VERSION ""

NS_ :

BS_:

BU_: IRTS_RL TLM DAS STEER IRTS_FL DAS STEER DAS IRTS_FR IRTS_FL DAS DAS TELEMETRY CONTROL DAS DAS DAS DAS DAS TELEMETRY DAS STEER IRTS_FR DAS IRTS_RR STEER DAS DAS IRTS_FR IRTS_FL IRTS_RR IRTS_FR DAS IRTS_RR IRTS_FL DAS TLM DAS IMU DAS DAS DAS STEER DAS IRTS_RL TLM IRTS_RR IRTS_RL TLM IMU STEER IRTS_RL

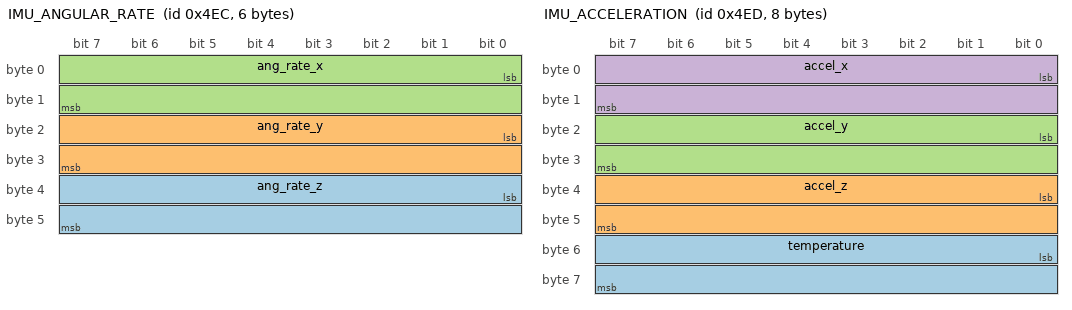
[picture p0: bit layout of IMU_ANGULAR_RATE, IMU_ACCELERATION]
BO_ 1260 IMU_ANGULAR_RATE: 6 Vector__XXX
 SG_ ang_rate_z : 32|16@1+ (0.05982905982905983,0) [0|245] "" Vector__XXX
 SG_ ang_rate_y : 16|16@1+ (0.05982905982905983,0) [0|245] "" Vector__XXX
 SG_ ang_rate_x : 0|16@1+ (0.05982905982905983,0) [0|245] "" Vector__XXX

BO_ 1261 IMU_ACCELERATION: 8 Vector__XXX
 SG_ temperature : 48|16@1- (1,-32768) [-32768|32767] "" Vector__XXX
 SG_ accel_z : 32|16@1+ (0.007820136852394917,0) [0|8] "" Vector__XXX
 SG_ accel_y : 16|16@1+ (0.007820136852394917,0) [0|8] "" Vector__XXX
 SG_ accel_x : 0|16@1+ (0.007820136852394917,0) [0|8] "" Vector__XXX

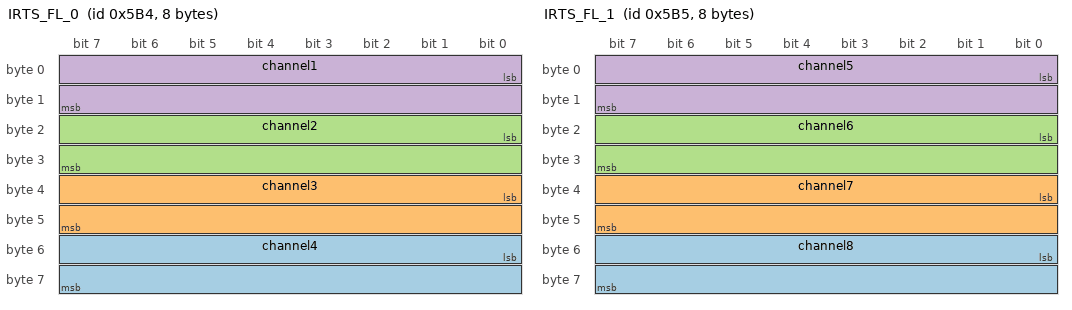
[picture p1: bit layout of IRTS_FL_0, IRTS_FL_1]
BO_ 1460 IRTS_FL_0: 8 Vector__XXX
 SG_ channel4 : 48|16@1+ (0.09775171065493646,-100) [-100|0] "" Vector__XXX
 SG_ channel3 : 32|16@1+ (0.09775171065493646,-100) [-100|0] "" Vector__XXX
 SG_ channel2 : 16|16@1+ (0.09775171065493646,-100) [-100|0] "" Vector__XXX
 SG_ channel1 : 0|16@1+ (0.09775171065493646,-100) [-100|0] "" Vector__XXX

BO_ 1461 IRTS_FL_1: 8 Vector__XXX
 SG_ channel8 : 48|16@1+ (0.09775171065493646,-100) [-100|0] "" Vector__XXX
 SG_ channel7 : 32|16@1+ (0.09775171065493646,-100) [-100|0] "" Vector__XXX
 SG_ channel6 : 16|16@1+ (0.09775171065493646,-100) [-100|0] "" Vector__XXX
 SG_ channel5 : 0|16@1+ (0.09775171065493646,-100) [-100|0] "" Vector__XXX

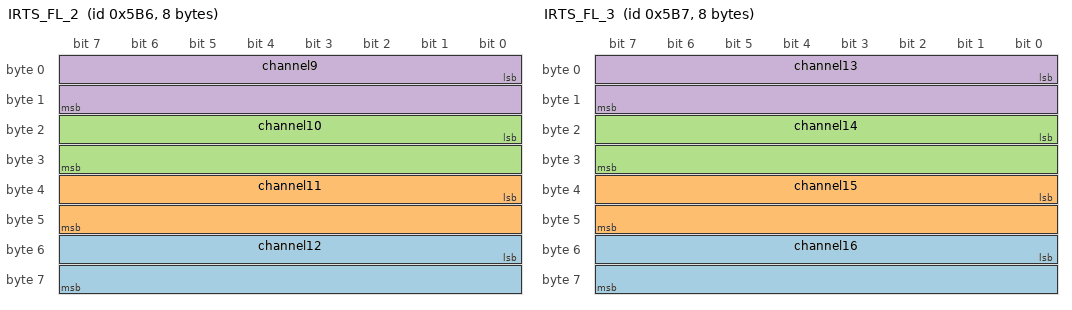
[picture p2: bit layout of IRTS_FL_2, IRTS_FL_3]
BO_ 1462 IRTS_FL_2: 8 Vector__XXX
 SG_ channel12 : 48|16@1+ (0.09775171065493646,-100) [-100|0] "" Vector__XXX
 SG_ channel11 : 32|16@1+ (0.09775171065493646,-100) [-100|0] "" Vector__XXX
 SG_ channel10 : 16|16@1+ (0.09775171065493646,-100) [-100|0] "" Vector__XXX
 SG_ channel9 : 0|16@1+ (0.09775171065493646,-100) [-100|0] "" Vector__XXX

BO_ 1463 IRTS_FL_3: 8 Vector__XXX
 SG_ channel16 : 48|16@1+ (0.09775171065493646,-100) [-100|0] "" Vector__XXX
 SG_ channel15 : 32|16@1+ (0.09775171065493646,-100) [-100|0] "" Vector__XXX
 SG_ channel14 : 16|16@1+ (0.09775171065493646,-100) [-100|0] "" Vector__XXX
 SG_ channel13 : 0|16@1+ (0.09775171065493646,-100) [-100|0] "" Vector__XXX

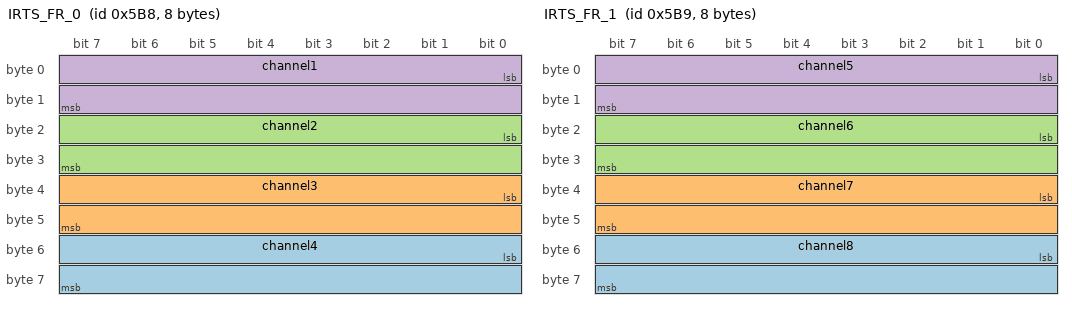
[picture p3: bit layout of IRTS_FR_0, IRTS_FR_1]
BO_ 1464 IRTS_FR_0: 8 Vector__XXX
 SG_ channel4 : 48|16@1+ (0.09775171065493646,-100) [-100|0] "" Vector__XXX
 SG_ channel3 : 32|16@1+ (0.09775171065493646,-100) [-100|0] "" Vector__XXX
 SG_ channel2 : 16|16@1+ (0.09775171065493646,-100) [-100|0] "" Vector__XXX
 SG_ channel1 : 0|16@1+ (0.09775171065493646,-100) [-100|0] "" Vector__XXX

BO_ 1465 IRTS_FR_1: 8 Vector__XXX
 SG_ channel8 : 48|16@1+ (0.09775171065493646,-100) [-100|0] "" Vector__XXX
 SG_ channel7 : 32|16@1+ (0.09775171065493646,-100) [-100|0] "" Vector__XXX
 SG_ channel6 : 16|16@1+ (0.09775171065493646,-100) [-100|0] "" Vector__XXX
 SG_ channel5 : 0|16@1+ (0.09775171065493646,-100) [-100|0] "" Vector__XXX

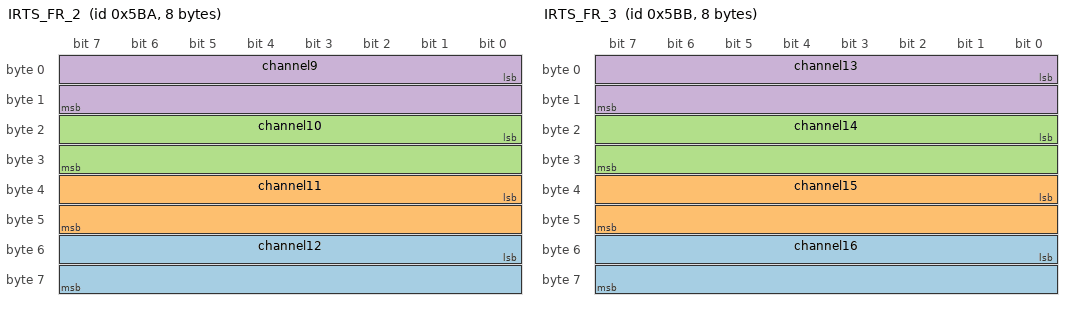
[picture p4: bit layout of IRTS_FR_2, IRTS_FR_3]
BO_ 1466 IRTS_FR_2: 8 Vector__XXX
 SG_ channel12 : 48|16@1+ (0.09775171065493646,-100) [-100|0] "" Vector__XXX
 SG_ channel11 : 32|16@1+ (0.09775171065493646,-100) [-100|0] "" Vector__XXX
 SG_ channel10 : 16|16@1+ (0.09775171065493646,-100) [-100|0] "" Vector__XXX
 SG_ channel9 : 0|16@1+ (0.09775171065493646,-100) [-100|0] "" Vector__XXX

BO_ 1467 IRTS_FR_3: 8 Vector__XXX
 SG_ channel16 : 48|16@1+ (0.09775171065493646,-100) [-100|0] "" Vector__XXX
 SG_ channel15 : 32|16@1+ (0.09775171065493646,-100) [-100|0] "" Vector__XXX
 SG_ channel14 : 16|16@1+ (0.09775171065493646,-100) [-100|0] "" Vector__XXX
 SG_ channel13 : 0|16@1+ (0.09775171065493646,-100) [-100|0] "" Vector__XXX

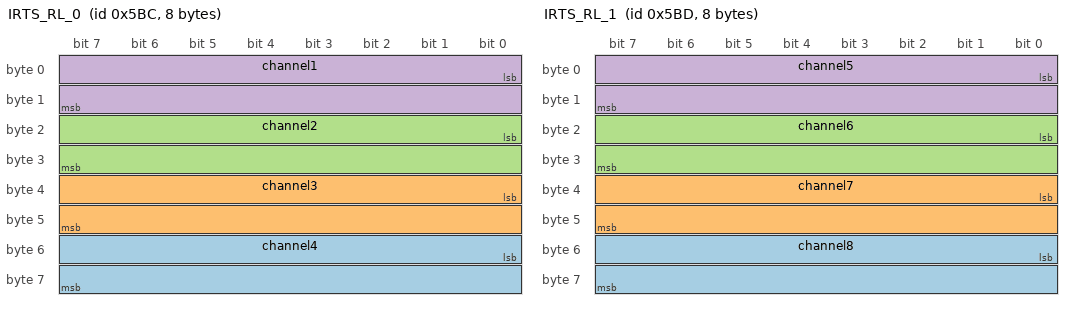
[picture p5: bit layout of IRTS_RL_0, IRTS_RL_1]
BO_ 1468 IRTS_RL_0: 8 Vector__XXX
 SG_ channel4 : 48|16@1+ (0.09775171065493646,-100) [-100|0] "" Vector__XXX
 SG_ channel3 : 32|16@1+ (0.09775171065493646,-100) [-100|0] "" Vector__XXX
 SG_ channel2 : 16|16@1+ (0.09775171065493646,-100) [-100|0] "" Vector__XXX
 SG_ channel1 : 0|16@1+ (0.09775171065493646,-100) [-100|0] "" Vector__XXX

BO_ 1469 IRTS_RL_1: 8 Vector__XXX
 SG_ channel8 : 48|16@1+ (0.09775171065493646,-100) [-100|0] "" Vector__XXX
 SG_ channel7 : 32|16@1+ (0.09775171065493646,-100) [-100|0] "" Vector__XXX
 SG_ channel6 : 16|16@1+ (0.09775171065493646,-100) [-100|0] "" Vector__XXX
 SG_ channel5 : 0|16@1+ (0.09775171065493646,-100) [-100|0] "" Vector__XXX

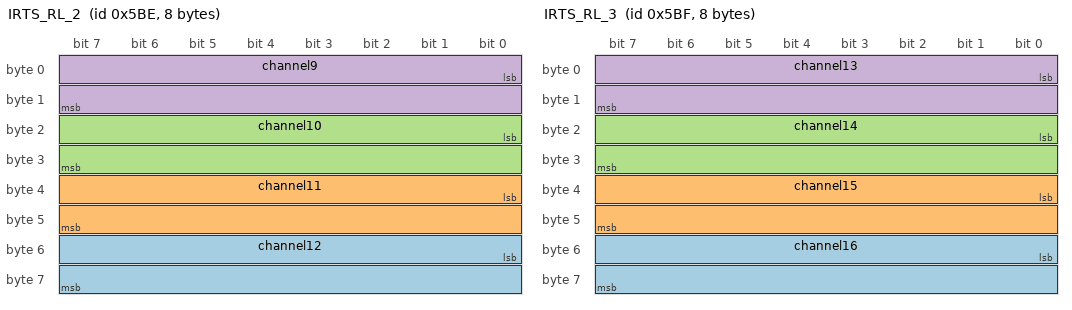
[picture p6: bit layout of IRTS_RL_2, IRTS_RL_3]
BO_ 1470 IRTS_RL_2: 8 Vector__XXX
 SG_ channel12 : 48|16@1+ (0.09775171065493646,-100) [-100|0] "" Vector__XXX
 SG_ channel11 : 32|16@1+ (0.09775171065493646,-100) [-100|0] "" Vector__XXX
 SG_ channel10 : 16|16@1+ (0.09775171065493646,-100) [-100|0] "" Vector__XXX
 SG_ channel9 : 0|16@1+ (0.09775171065493646,-100) [-100|0] "" Vector__XXX

BO_ 1471 IRTS_RL_3: 8 Vector__XXX
 SG_ channel16 : 48|16@1+ (0.09775171065493646,-100) [-100|0] "" Vector__XXX
 SG_ channel15 : 32|16@1+ (0.09775171065493646,-100) [-100|0] "" Vector__XXX
 SG_ channel14 : 16|16@1+ (0.09775171065493646,-100) [-100|0] "" Vector__XXX
 SG_ channel13 : 0|16@1+ (0.09775171065493646,-100) [-100|0] "" Vector__XXX

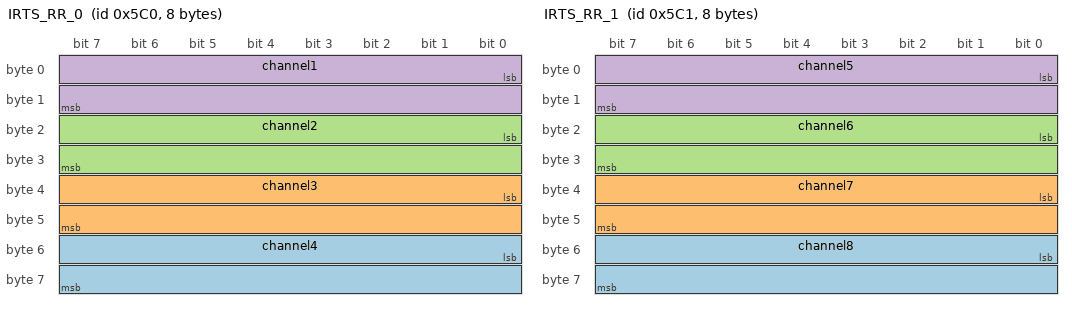
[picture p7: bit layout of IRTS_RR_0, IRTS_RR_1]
BO_ 1472 IRTS_RR_0: 8 Vector__XXX
 SG_ channel4 : 48|16@1+ (0.09775171065493646,-100) [-100|0] "" Vector__XXX
 SG_ channel3 : 32|16@1+ (0.09775171065493646,-100) [-100|0] "" Vector__XXX
 SG_ channel2 : 16|16@1+ (0.09775171065493646,-100) [-100|0] "" Vector__XXX
 SG_ channel1 : 0|16@1+ (0.09775171065493646,-100) [-100|0] "" Vector__XXX

BO_ 1473 IRTS_RR_1: 8 Vector__XXX
 SG_ channel8 : 48|16@1+ (0.09775171065493646,-100) [-100|0] "" Vector__XXX
 SG_ channel7 : 32|16@1+ (0.09775171065493646,-100) [-100|0] "" Vector__XXX
 SG_ channel6 : 16|16@1+ (0.09775171065493646,-100) [-100|0] "" Vector__XXX
 SG_ channel5 : 0|16@1+ (0.09775171065493646,-100) [-100|0] "" Vector__XXX

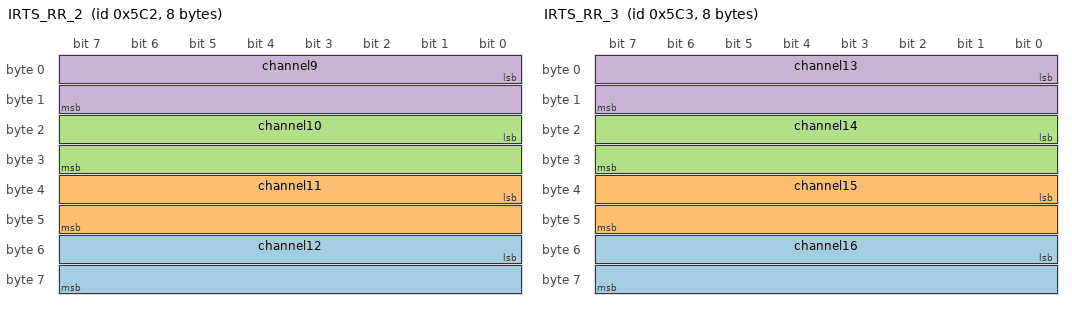
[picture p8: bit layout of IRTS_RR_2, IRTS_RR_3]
BO_ 1474 IRTS_RR_2: 8 Vector__XXX
 SG_ channel12 : 48|16@1+ (0.09775171065493646,-100) [-100|0] "" Vector__XXX
 SG_ channel11 : 32|16@1+ (0.09775171065493646,-100) [-100|0] "" Vector__XXX
 SG_ channel10 : 16|16@1+ (0.09775171065493646,-100) [-100|0] "" Vector__XXX
 SG_ channel9 : 0|16@1+ (0.09775171065493646,-100) [-100|0] "" Vector__XXX

BO_ 1475 IRTS_RR_3: 8 Vector__XXX
 SG_ channel16 : 48|16@1+ (0.09775171065493646,-100) [-100|0] "" Vector__XXX
 SG_ channel15 : 32|16@1+ (0.09775171065493646,-100) [-100|0] "" Vector__XXX
 SG_ channel14 : 16|16@1+ (0.09775171065493646,-100) [-100|0] "" Vector__XXX
 SG_ channel13 : 0|16@1+ (0.09775171065493646,-100) [-100|0] "" Vector__XXX

BO_ 1024 GPS_COORDS: 8 Vector__XXX
 SG_ longitude : 32|32@1+ (1,0) [0|4294967295] "" Vector__XXX
 SG_ latitude : 0|32@1+ (1,0) [0|4294967295] "" Vector__XXX

BO_ 1056 GPS_SPEED: 2 Vector__XXX
 SG_ speed : 0|16@1+ (1,0) [0|65535] "" Vector__XXX

BO_ 1088 LAP_COUNT: 5 Vector__XXX
 SG_ lap_time : 8|32@1+ (1,0) [0|4294967295] "" Vector__XXX
 SG_ lap_count : 0|8@1+ (1,0) [0|255] "" Vector__XXX

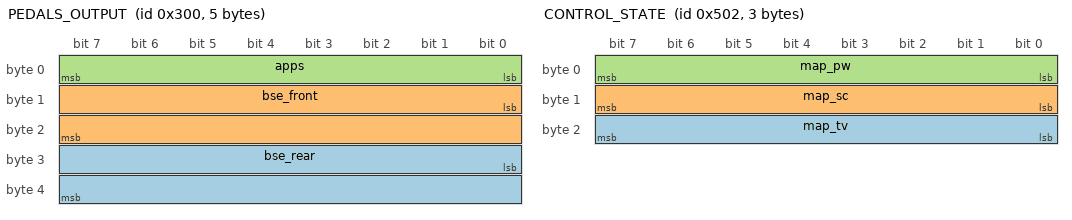
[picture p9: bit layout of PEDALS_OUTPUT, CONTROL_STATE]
BO_ 768 PEDALS_OUTPUT: 5 Vector__XXX
 SG_ bse_rear : 24|16@1+ (0.0015259021896696422,0) [0|100] "" Vector__XXX
 SG_ bse_front : 8|16@1+ (0.0015259021896696422,0) [0|100] "" Vector__XXX
 SG_ apps : 0|8@1+ (1,0) [0|255] "" Vector__XXX

BO_ 257 STEERING_ANGLE: 4 Vector__XXX
 SG_ angle : 0|32@1+ (1,0) [0|4294967295] "" Vector__XXX

BO_ 1282 CONTROL_STATE: 3 Vector__XXX
 SG_ map_tv : 16|8@1+ (0.06666666666666667,0) [0|1] "" Vector__XXX
 SG_ map_sc : 8|8@1+ (0.06666666666666667,0) [0|1] "" Vector__XXX
 SG_ map_pw : 0|8@1+ (0.1,-0.5) [-0.5|1] "" Vector__XXX

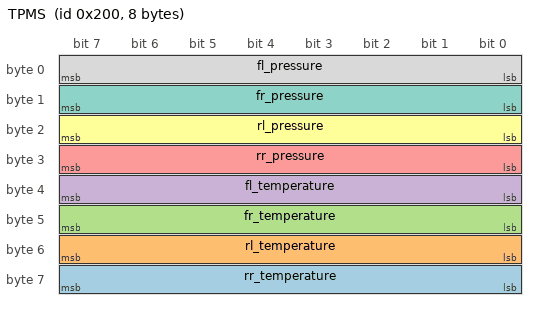
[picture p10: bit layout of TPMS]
BO_ 512 TPMS: 8 Vector__XXX
 SG_ rr_temperature : 56|8@1+ (1,0) [0|255] "" Vector__XXX
 SG_ rl_temperature : 48|8@1+ (1,0) [0|255] "" Vector__XXX
 SG_ fr_temperature : 40|8@1+ (1,0) [0|255] "" Vector__XXX
 SG_ fl_temperature : 32|8@1+ (1,0) [0|255] "" Vector__XXX
 SG_ rr_pressure : 24|8@1+ (0.0967741935483871,0) [0|3] "" Vector__XXX
 SG_ rl_pressure : 16|8@1+ (0.0967741935483871,0) [0|3] "" Vector__XXX
 SG_ fr_pressure : 8|8@1+ (0.0967741935483871,0) [0|3] "" Vector__XXX
 SG_ fl_pressure : 0|8@1+ (0.0967741935483871,0) [0|3] "" Vector__XXX

BO_ 771 LC_STATUS: 6 Vector__XXX
 SG_ lap_number : 32|16@1- (1,-32768) [-32768|32767] "" Vector__XXX
 SG_ last_time : 0|32@1+ (1,0) [0|4294967295] "" Vector__XXX

CM_ BO_ 1260 "Inertial Measurement Unit [x,y,z]-axis angular rate value. 0.01dps per bit, Big-Endian, 16bit Total, signed";
CM_ BO_ 1261 "Inertial Measurement Unit [x,y,z]-axis acceleration value. 0.01g per bit, Big-Endian, 16bit Total, signed";
CM_ BO_ 1460 "Front Left wheel InfraRed Temperature Sensor data, channels 1 through 4. 0.1˚C per bit, -100˚C offset, Big-Endian, 16bit Total, unsigned.";
CM_ BO_ 1461 "Front Left wheel InfraRed Temperature Sensor data, channels 5 through 8. 0.1˚C per bit, -100˚C offset, Big-Endian, 16bit Total, unsigned.";
CM_ BO_ 1462 "Front Left wheel InfraRed Temperature Sensor data, channels 9 through 12. 0.1˚C per bit, -100˚C offset, Big-Endian, 16bit Total, unsigned.";
CM_ BO_ 1463 "Front Left wheel InfraRed Temperature Sensor data, channels 13 through 16. 0.1˚C per bit, -100˚C offset, Big-Endian, 16bit Total, unsigned.";
CM_ BO_ 1464 "Front Right wheel InfraRed Temperature Sensor data, channels 1 through 4. 0.1˚C per bit, -100˚C offset, Big-Endian, 16bit Total, unsigned.";
CM_ BO_ 1465 "Front Right wheel InfraRed Temperature Sensor data, channels 5 through 8. 0.1˚C per bit, -100˚C offset, Big-Endian, 16bit Total, unsigned.";
CM_ BO_ 1466 "Front Right wheel InfraRed Temperature Sensor data, channels 9 through 12. 0.1˚C per bit, -100˚C offset, Big-Endian, 16bit Total, unsigned.";
CM_ BO_ 1467 "Front Right wheel InfraRed Temperature Sensor data, channels 13 through 16. 0.1˚C per bit, -100˚C offset, Big-Endian, 16bit Total, unsigned.";
CM_ BO_ 1468 "Rear Left wheel InfraRed Temperature Sensor data, channels 1 through 4. 0.1˚C per bit, -100˚C offset, Big-Endian, 16bit Total, unsigned.";
CM_ BO_ 1469 "Rear Left wheel InfraRed Temperature Sensor data, channels 5 through 8. 0.1˚C per bit, -100˚C offset, Big-Endian, 16bit Total, unsigned.";
CM_ BO_ 1470 "Rear Left wheel InfraRed Temperature Sensor data, channels 9 through 12. 0.1˚C per bit, -100˚C offset, Big-Endian, 16bit Total, unsigned.";
CM_ BO_ 1471 "Rear Left wheel InfraRed Temperature Sensor data, channels 13 through 16. 0.1˚C per bit, -100˚C offset, Big-Endian, 16bit Total, unsigned.";
CM_ BO_ 1472 "Rear Right wheel InfraRed Temperature Sensor data, channels 1 through 4. 0.1˚C per bit, -100˚C offset, Big-Endian, 16bit Total, unsigned.";
CM_ BO_ 1473 "Rear Right wheel InfraRed Temperature Sensor data, channels 5 through 8. 0.1˚C per bit, -100˚C offset, Big-Endian, 16bit Total, unsigned.";
CM_ BO_ 1474 "Rear Right wheel InfraRed Temperature Sensor data, channels 9 through 12. 0.1˚C per bit, -100˚C offset, Big-Endian, 16bit Total, unsigned.";
CM_ BO_ 1475 "Rear Right wheel InfraRed Temperature Sensor data, channels 13 through 16. 0.1˚C per bit, -100˚C offset, Big-Endian, 16bit Total, unsigned.";
CM_ BO_ 1024 "Coordinates received from GPS";
CM_ BO_ 1056 "Speed received from GPS";
CM_ BO_ 1088 "Lap counter and associated timestamp";
CM_ BO_ 768 "Pedal output, already calibrated";
CM_ BO_ 257 "Steering angle in degrees";
CM_ BO_ 1282 "Send status of traction control";
CM_ BO_ 512 "Tire Pressure Monitoring System, pressure and temperature of each tire";
CM_ BO_ 771 "Session laps status, lap_number is -1 in case of OUT lap";
BA_DEF_ BO_  "GenMsgCycleTime" INT 0 65535;
BA_DEF_DEF_  "GenMsgCycleTime" 0;
BA_ "GenMsgCycleTime" BO_ 768 10;
BA_ "GenMsgCycleTime" BO_ 257 10;
BA_ "GenMsgCycleTime" BO_ 1282 100;
